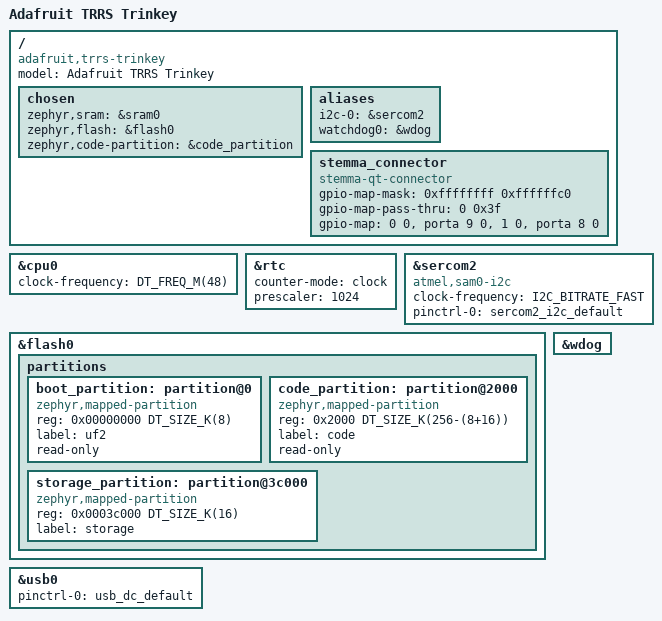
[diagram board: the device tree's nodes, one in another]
/*
 * Copyright (c) 2018 Google LLC.
 * Copyright (c) 2026 Perry Naseck, MIT Media Lab <pnaseck@media.mit.edu>
 *
 * SPDX-License-Identifier: Apache-2.0
 */

/dts-v1/;
#include <atmel/samd21.dtsi>
#include <atmel/samx2xx18.dtsi>
#include <freq.h>
#include "adafruit_trrs_trinkey-pinctrl.dtsi"

/ {
	compatible = "adafruit,trrs-trinkey", "atmel,samd21e18a", "atmel,samd21";
	model = "Adafruit TRRS Trinkey";

	chosen {
		zephyr,sram = &sram0;
		zephyr,flash = &flash0;
		zephyr,code-partition = &code_partition;
	};

	/* These aliases are provided for compatibility with samples */
	aliases {
		i2c-0 = &sercom2;
		watchdog0 = &wdog;
	};

	stemma_connector: stemma_connector {
		compatible = "stemma-qt-connector";
		#gpio-cells = <2>;
		gpio-map-mask = <0xffffffff 0xffffffc0>;
		gpio-map-pass-thru = <0 0x3f>;
		gpio-map = <0 0 &porta 9 0>, /* SCL */
			   <1 0 &porta 8 0>; /* SDA */
	};
};

&cpu0 {
	clock-frequency = <DT_FREQ_M(48)>;
};

&rtc {
	counter-mode = "clock";
	prescaler = <1024>;
	status = "okay";
};

zephyr_i2c: &sercom2 {
	compatible = "atmel,sam0-i2c";
	clock-frequency = <I2C_BITRATE_FAST>;
	#address-cells = <1>;
	#size-cells = <0>;

	pinctrl-0 = <&sercom2_i2c_default>;
	pinctrl-names = "default";
	status = "okay";
};

&flash0 {
	partitions {
		ranges;
		#address-cells = <1>;
		#size-cells = <1>;

		boot_partition: partition@0 {
			compatible = "zephyr,mapped-partition";
			reg = <0x00000000 DT_SIZE_K(8)>;
			label = "uf2";
			read-only;
		};

		code_partition: partition@2000 {
			compatible = "zephyr,mapped-partition";
			reg = <0x2000 DT_SIZE_K(256-(8+16))>;
			label = "code";
			read-only;
		};

		/*
		 * The final 16 KiB is reserved for the application.
		 * Storage partition will be used by FCB/LittleFS/NVS
		 * if enabled.
		 */
		storage_partition: partition@3c000 {
			compatible = "zephyr,mapped-partition";
			reg = <0x0003c000 DT_SIZE_K(16)>;
			label = "storage";
		};
	};
};

&wdog {
	status = "okay";
};

zephyr_udc0: &usb0 {

	pinctrl-0 = <&usb_dc_default>;
	pinctrl-names = "default";
	status = "okay";
};

#include <../boards/common/usb/cdc_acm_serial.dtsi>
